# earlgrey register map
Vendor: lowRISC OpenTitan; File version: snapshot-20191101-1-518-g9293d546-dirty
CPU: RISCV 0, little endian, MPU, no FPU, 0 interrupt priority bits
Registers are 32-bit, read-write, reset 0x0 unless marked. A register's access mark holds for its fields unless they carry their own. Offsets are from the block's base; [hi:lo] are bit positions; lines under a group give offsets from that group; {n}, {i} and the like mark numbered series.

## aes
Base 0x40110000
0x00 KEY group — Initial Key Registers. Loaded into the internal Full Key register upon starting encryption/decryption of the next block. Can only be updated when the AES unit is idle. If the AES unit is non-idle, writes to these registers are ignored. All key registers must be updated when the key is changed, regardless of key length (write 0 for unusued bits). The order in which the registers are updated does not matter.
  {0x0+4j} KEY{j} wo reset not defined (j=0..7) — Initial Key Registers. Loaded into the internal Full Key register upon starting encryption/decryption of the next block. Can only be updated when the AES unit is idle. If the AES unit is non-idle, writes to these registers are ignored. All key registers must be updated when the key is changed, regardless of key length (write 0 for unusued bits). The order in which the registers are updated does not matter.
    [31:0] key{j} — Initial Key for KEY{j}
0x20 DATA_IN group — Input Data Registers. Loaded into the internal State register upon starting encryption/decryption of the next block. After that, the processor can update the Input Data Register. The order in which the registers are written does not matter.
  {0x0+4j} DATA_IN{j} wo reset not defined (j=0..3) — Input Data Registers. Loaded into the internal State register upon starting encryption/decryption of the next block. After that, the processor can update the Input Data Register. The order in which the registers are written does not matter.
    [31:0] data_in{j} — Input Data for DATA_IN{j}
0x30 DATA_OUT group — Output Data Register. Holds the output data produced by the AES unit during the last encryption/decryption operation. If FORCE_DATA_OVERWRITE=0 (see Control Register), the AES unit is stalled when the previous output data has not yet been read and is about to be overwritten. The order in which the registers are read does not matter.
  {0x0+4j} DATA_OUT{j} ro (j=0..3) — Output Data Register. Holds the output data produced by the AES unit during the last encryption/decryption operation. If FORCE_DATA_OVERWRITE=0 (see Control Register), the AES unit is stalled when the previous output data has not yet been read and is about to be overwritten. The order in which the registers are read does not matter.
    [31:0] data_out{j} — Output Data for DATA_OUT{j}
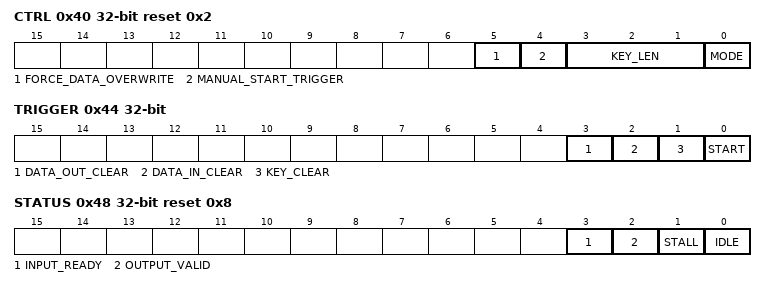
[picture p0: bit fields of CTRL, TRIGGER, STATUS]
0x40 CTRL reset 0x2 — Control Register. Can only be updated when the AES unit is idle. If the AES unit is non-idle, writes to this register are ignored.
  [5] FORCE_DATA_OVERWRITE — Control whether the AES unit is stalled during the last encryption/decryption cycle if the previous output data has not yet been read (0) or finishes the operation and overwrites the previous output data (1).
  [4] MANUAL_START_TRIGGER — Controls whether the AES unit should automatically start to encrypt/decrypt when it receives new input data (0) or wait for separate trigger signal before starting (1) (see Trigger Register).
  [3:1] KEY_LEN — 3-bit one-hot field to select AES key length: 128 bit (3'b001), 192 bit (3'b010) or 256 bit (3'b100). Invalid input values, i.e., value with multiple bits set, value 3'b000, and value 3'b010 in case 192-bit keys are not supported (because disabled at compile time) are mapped to 3'b001.
  [0] MODE — Select encryption(0) or decryption(1) operating mode of AES unit.
0x44 TRIGGER wo reset not defined
  [3] DATA_OUT_CLEAR — Keep current values in output registers (0) or clear those registers (1).
  [2] DATA_IN_CLEAR — Keep current values in input registers (0) or clear those registers (1).
  [1] KEY_CLEAR — Keep current values in Initial Key, internal Full Key and Decryption Key registers (0) or clear those registers (1).
  [0] START — Keep AES unit paused (0) or trigger the encryption/decryption of one data block (1).
0x48 STATUS ro reset 0x8
  [3] INPUT_READY — The AES unit is ready (1) to receive new data input via the DATA_IN registers or the present values in the DATA_IN registers have not yet been loaded into the module (0).
  [2] OUTPUT_VALID — The AES unit has no valid output (0) or has valid output data (1).
  [1] STALL — The AES unit is not stalled (0) or stalled (1) because there is previous output data that must be read by the processor before the AES unit can overwrite this data.
  [0] IDLE — The AES unit is idle (0) or busy (1).
